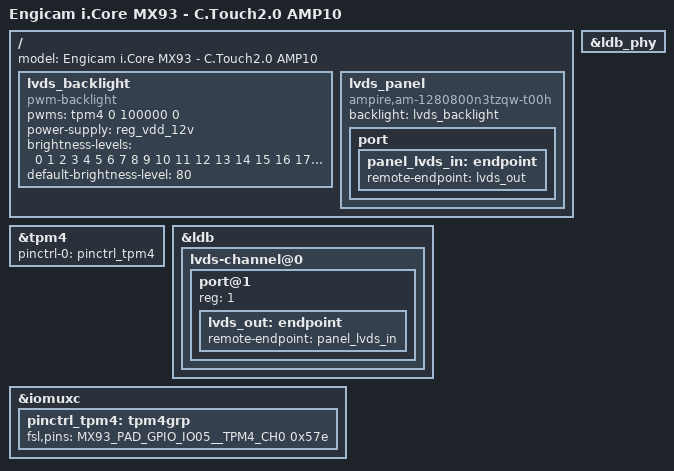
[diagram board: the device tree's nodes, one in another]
/*
 * Copyright 2021 Engicam srl
 * Copyright 2019 NXP
 *
 * This program is free software; you can redistribute it and/or
 * modify it under the terms of the GNU General Public License
 * as published by the Free Software Foundation; either version 2
 * of the License, or (at your option) any later version.
 *
 * This program is distributed in the hope that it will be useful,
 * but WITHOUT ANY WARRANTY; without even the implied warranty of
 * MERCHANTABILITY or FITNESS FOR A PARTICULAR PURPOSE.  See the
 * GNU General Public License for more details.
 */

#include "imx93-icore-ctouch2.dts"

/ {
	model = "Engicam i.Core MX93 - C.Touch2.0 AMP10";

	lvds_backlight: lvds_backlight {
		compatible = "pwm-backlight";
		pwms = <&tpm4 0 100000 0>;
		power-supply = <&reg_vdd_12v>;
		status = "okay";

		brightness-levels = < 0  1  2  3  4  5  6  7  8  9
				     10 11 12 13 14 15 16 17 18 19
				     20 21 22 23 24 25 26 27 28 29
				     30 31 32 33 34 35 36 37 38 39
				     40 41 42 43 44 45 46 47 48 49
				     50 51 52 53 54 55 56 57 58 59
				     60 61 62 63 64 65 66 67 68 69
				     70 71 72 73 74 75 76 77 78 79
				     80 81 82 83 84 85 86 87 88 89
				     90 91 92 93 94 95 96 97 98 99
				    100>;
		default-brightness-level = <80>;
	};

	lvds_panel {
		compatible = "ampire,am-1280800n3tzqw-t00h";
		backlight = <&lvds_backlight>;

		port {
			panel_lvds_in: endpoint {
				remote-endpoint = <&lvds_out>;
			};
		};
	};	
};

&tpm4 {
	pinctrl-names = "default";
	pinctrl-0 = <&pinctrl_tpm4>;
	status = "okay";
};


&ldb {
	status = "okay";

	lvds-channel@0 {
		status = "okay";

		port@1 {
			reg = <1>;

			lvds_out: endpoint {
				remote-endpoint = <&panel_lvds_in>;
			};
		};
	};
};

&ldb_phy {
	status = "okay";
};

&iomuxc {

	pinctrl_tpm4: tpm4grp {
		fsl,pins = <
			MX93_PAD_GPIO_IO05__TPM4_CH0			0x57e
		>;
	};
};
